# A31L12x register map
Vendor: VENDOR ABOV Semiconductor Co., Ltd.; Series: A31L12x; File version: 1.0
CPU: CM0+ r0p1, little endian, no MPU, no FPU, VTOR, 2 interrupt priority bits
Registers are 32-bit, read-write, reset 0x0 unless marked. A register's access mark holds for its fields unless they carry their own. Offsets are from the block's base; [hi:lo] are bit positions; {n}, {i} and the like mark numbered series.

## LPUART — Low Power UART
Base 0x40005C00
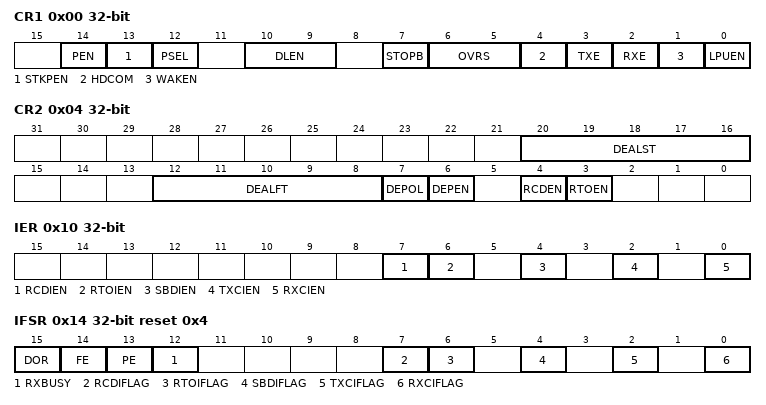
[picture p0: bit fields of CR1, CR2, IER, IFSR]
0x00 CR1 — LPUART Control Register 1
  [14] PEN — Parity Enable
  [13] STKPEN — Stick Parity Enable
  [12] PSEL — Parity Selection
  [10:9] DLEN — Data Length Selection
  [7] STOPB — Stop
  [6:5] OVRS — Oversampling Selection
  [4] HDCOM — 1-wire Half-Duplex Communication
  [3] TXE — Enable the transmitter unit.
  [2] RXE — Enable the receiver unit.
  [1] WAKEN — Wake-Up Function bit in Deep Sleep Mode
  [0] LPUEN — Low Power UART Enable
0x04 CR2 — LPUART Control Register 2
  [20:16] DEALST — DE Pin Active Level Start Time
  [12:8] DEALFT — DE Pin Active Level Finish Time
  [7] DEPOL — DE Pin Polarity Selection
  [6] DEPEN — DE Pin Function Enable
  [4] RCDEN — Receive Character Detection Function Enable
  [3] RTOEN — Receive Time Out Function Enable
0x10 IER — LPUART Interrupt Enable Register
  [7] RCDIEN — Receive Character Detection Interrupt Enable
  [6] RTOIEN — Receive Time Out Interrupt Enable
  [4] SBDIEN — Start Bit Detection Interrupt Enable bit in Deep Sleep Mode
  [2] TXCIEN — Transmit Complete Interrupt Enable
  [0] RXCIEN — Receive Data Register Not Empty Interrupt Enable
0x14 IFSR reset 0x4 — LPUART Interrupt Flag and Status Register
  [15] DOR — Data Overrun
  [14] FE — Frame Error
  [13] PE — Parity Error
  [12] RXBUSY ro — RXD Line Busy
  [7] RCDIFLAG — Receive Character detection Interrupt Flag
  [6] RTOIFLAG — Receive Time Out Interrupt Flag
  [4] SBDIFLAG — Start Bit Detection Interrupt Flag
  [2] TXCIFLAG — Transmit Complete Interrupt Flag
  [0] RXCIFLAG — Receive Data Register Not Empty Interrupt Flag
0x18 RDR ro — LPUART Receive Data Register
  [7:0] RDATA — Receive Data
0x1C TDR — LPUART Transmit Data Register
  [7:0] TDATA — Transmit Data
0x20 BDR reset 0xFFFF — LPUART Baud Rate Data Register
  [15:0] BDATA — These bits are used to generate baud rate
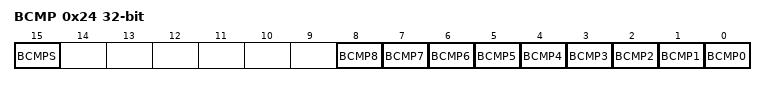
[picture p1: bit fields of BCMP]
0x24 BCMP — LPUART Baud Rate Compensation Register
  [15] BCMPS — Baud Rate Compensation Sign
  [n] BCMP{n} (n=0..8) — Baud Rate Compensation {n}
0x28 RTODR reset 0xFFFF — LPUART Receive Time Out Data Register
  [23:0] RTOD — LPUART Receive Time Out Data
0x2C RCDR — LPUART Receive Character Detection Data Register
  [7:0] RCDD — LPUART Receive Character Detection Data
0x30 DLYDR — LPUART Tx Delay Time Data Register
  [7:0] DLYD — LPUART Tx Delay Data

## SPIn
Base 0x57000000
Same registers: SPI0 0x40005800, SPI1 0x40005880
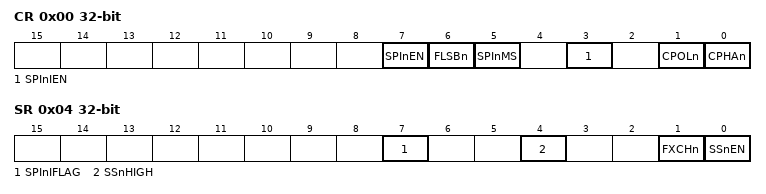
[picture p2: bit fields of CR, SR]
0x00 CR — SPIn Control Register
  [7] SPInEN — SPIn Operation Control
    0=Disable SPIn operation; 1=Enable SPIn operation
  [6] FLSBn — Data Transmission Sequence Selection
    0=msbFirst; 1=lsbFirst
  [5] SPInMS — Master/Slave Selection
    0=Slave mode; 1=Master mode
  [3] SPInIEN — SPIn Interrupt Enable
    0=Disable SPIn interrupt; 1=Enable SPIn interrupt
  [1] CPOLn — Selects the clock polarity of SCK
    0=IdleLow (SCK to 0 when idle); 1=IdleHigh (SCK to 1 when idle)
  [0] CPHAn — The CPOLn and this bit determine if data are sampled on the leading or trailing edge of SCK
    0=StartIdle (Start with idle state.); 1=StartInverted (Start with inverted idle state.)
0x04 SR — SPIn Status Register
  [7] SPInIFLAG — SPIn Interrupt Flag
    0=No request occurred; 1=Request occurred
  [4] SSnHIGH — This bit is set when the SSn pin goes high level during the pin is the corresponding function
    0=NoEffect; 1=High (The SSn pin has gone from low level to high)
  [1] FXCHn — SPIn Pin Function Exchange Control
    0=NoEffect; 1=Exchange MOSIn and MISOn function
  [0] SSnEN — SSn Pin Operation Control
    0=Disable SSn pin operation; 1=Enable SSn pin operation
0x08 RDR ro — SPIn Receive Data Register
  [7:0] RDATA — SPIn Receive Data
0x0C TDR — SPIn Transmit Data Register
  [7:0] TDATA — SPIn Transmit Data
0x10 PREDR reset 0x3FF — SPIn Prescaler Data Register
  [9:0] PRED — The value in this register is used to generate an SCK clock
